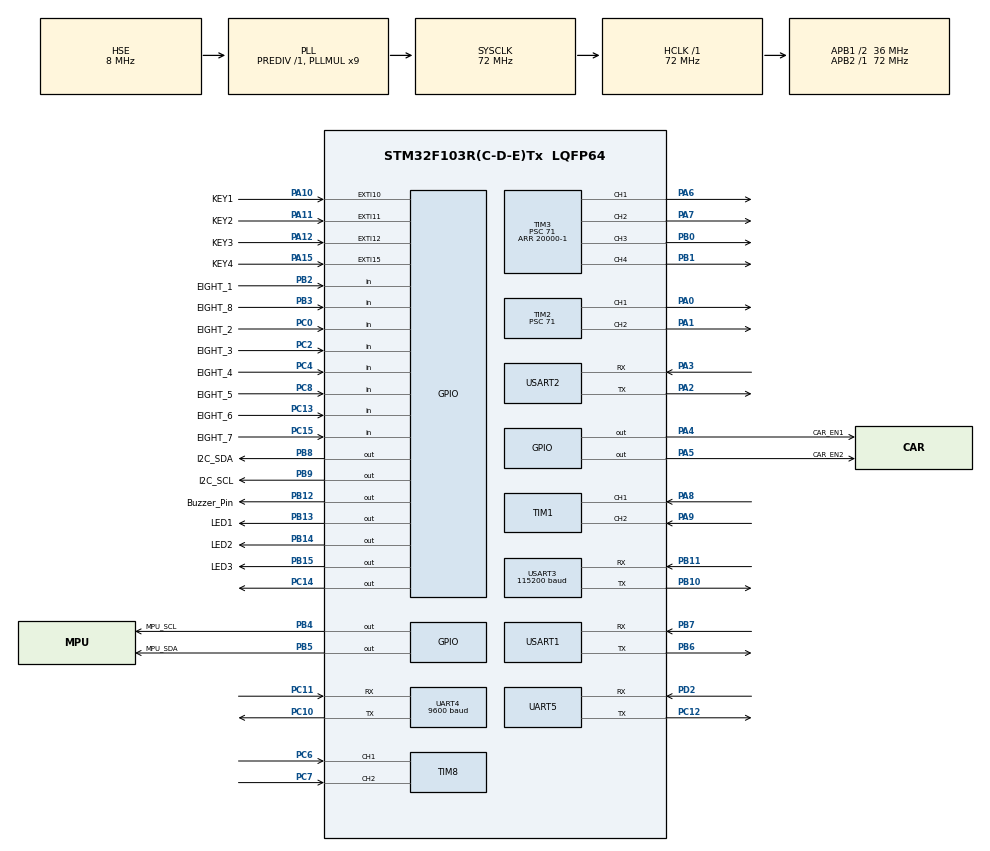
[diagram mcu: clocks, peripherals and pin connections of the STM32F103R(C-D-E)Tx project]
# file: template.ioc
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Dma.Request0=USART3_TX
Dma.Request1=USART3_RX
Dma.Request2=USART2_RX
Dma.Request3=USART2_TX
Dma.Request4=UART4_RX
Dma.Request5=UART4_TX
Dma.UART4_RX.4.Direction=DMA_PERIPH_TO_MEMORY
Dma.UART4_RX.4.Instance=DMA2_Channel3
Dma.UART4_RX.4.MemDataAlignment=DMA_MDATAALIGN_BYTE
Dma.UART4_RX.4.MemInc=DMA_MINC_ENABLE
Dma.UART4_RX.4.Mode=DMA_NORMAL
Dma.UART4_RX.4.PeriphDataAlignment=DMA_PDATAALIGN_BYTE
Dma.UART4_RX.4.PeriphInc=DMA_PINC_DISABLE
Dma.UART4_RX.4.Priority=DMA_PRIORITY_LOW
Dma.UART4_TX.5.Direction=DMA_MEMORY_TO_PERIPH
Dma.UART4_TX.5.Instance=DMA2_Channel5
Dma.UART4_TX.5.MemDataAlignment=DMA_MDATAALIGN_BYTE
Dma.UART4_TX.5.MemInc=DMA_MINC_ENABLE
Dma.UART4_TX.5.Mode=DMA_NORMAL
Dma.UART4_TX.5.PeriphDataAlignment=DMA_PDATAALIGN_BYTE
Dma.UART4_TX.5.PeriphInc=DMA_PINC_DISABLE
Dma.UART4_TX.5.Priority=DMA_PRIORITY_LOW
Dma.USART2_RX.2.Direction=DMA_PERIPH_TO_MEMORY
Dma.USART2_RX.2.Instance=DMA1_Channel6
Dma.USART2_RX.2.MemDataAlignment=DMA_MDATAALIGN_BYTE
Dma.USART2_RX.2.MemInc=DMA_MINC_ENABLE
Dma.USART2_RX.2.Mode=DMA_NORMAL
Dma.USART2_RX.2.PeriphDataAlignment=DMA_PDATAALIGN_BYTE
Dma.USART2_RX.2.PeriphInc=DMA_PINC_DISABLE
Dma.USART2_RX.2.Priority=DMA_PRIORITY_LOW
Dma.USART2_TX.3.Direction=DMA_MEMORY_TO_PERIPH
Dma.USART2_TX.3.Instance=DMA1_Channel7
Dma.USART2_TX.3.MemDataAlignment=DMA_MDATAALIGN_BYTE
Dma.USART2_TX.3.MemInc=DMA_MINC_ENABLE
Dma.USART2_TX.3.Mode=DMA_NORMAL
Dma.USART2_TX.3.PeriphDataAlignment=DMA_PDATAALIGN_BYTE
Dma.USART2_TX.3.PeriphInc=DMA_PINC_DISABLE
Dma.USART2_TX.3.Priority=DMA_PRIORITY_LOW
Dma.USART3_RX.1.Direction=DMA_PERIPH_TO_MEMORY
Dma.USART3_RX.1.Instance=DMA1_Channel3
Dma.USART3_RX.1.MemDataAlignment=DMA_MDATAALIGN_BYTE
Dma.USART3_RX.1.MemInc=DMA_MINC_ENABLE
Dma.USART3_RX.1.Mode=DMA_NORMAL
Dma.USART3_RX.1.PeriphDataAlignment=DMA_PDATAALIGN_BYTE
Dma.USART3_RX.1.PeriphInc=DMA_PINC_DISABLE
Dma.USART3_RX.1.Priority=DMA_PRIORITY_LOW
Dma.USART3_TX.0.Direction=DMA_MEMORY_TO_PERIPH
Dma.USART3_TX.0.Instance=DMA1_Channel2
Dma.USART3_TX.0.MemDataAlignment=DMA_MDATAALIGN_BYTE
Dma.USART3_TX.0.MemInc=DMA_MINC_ENABLE
Dma.USART3_TX.0.Mode=DMA_NORMAL
Dma.USART3_TX.0.PeriphDataAlignment=DMA_PDATAALIGN_BYTE
Dma.USART3_TX.0.PeriphInc=DMA_PINC_DISABLE
Dma.USART3_TX.0.Priority=DMA_PRIORITY_LOW
Mcu.Family=STM32F1
Mcu.Name=STM32F103R(C-D-E)Tx
Mcu.Package=LQFP64
NVIC.DMA1_Channel2_IRQn=true\:0\:0\:false\:false\:true\:false\:true\:true
NVIC.DMA1_Channel3_IRQn=true\:0\:0\:false\:false\:true\:false\:true\:true
NVIC.DMA1_Channel6_IRQn=true\:0\:0\:false\:false\:true\:false\:true\:true
NVIC.DMA1_Channel7_IRQn=true\:0\:0\:false\:false\:true\:false\:true\:true
NVIC.DMA2_Channel3_IRQn=true\:0\:0\:false\:false\:true\:false\:true\:true
NVIC.DMA2_Channel4_5_IRQn=true\:0\:0\:false\:false\:true\:false\:true\:true
NVIC.EXTI15_10_IRQn=true\:1\:0\:true\:false\:true\:true\:true\:true
NVIC.PriorityGroup=NVIC_PRIORITYGROUP_4
NVIC.TIM1_UP_IRQn=true\:0\:0\:false\:false\:true\:true\:true\:true
NVIC.TIM2_IRQn=true\:2\:0\:true\:false\:true\:true\:true\:true
NVIC.TIM8_UP_IRQn=true\:0\:0\:false\:false\:true\:true\:true\:true
NVIC.UART4_IRQn=true\:2\:0\:true\:false\:true\:true\:true\:true
NVIC.USART1_IRQn=true\:2\:0\:true\:false\:true\:true\:true\:true
NVIC.USART2_IRQn=true\:2\:0\:true\:false\:true\:true\:true\:true
NVIC.USART3_IRQn=true\:2\:0\:true\:false\:true\:true\:true\:true
PA0-WKUP.Signal=S_TIM2_CH1_ETR
PA1.Signal=S_TIM2_CH2
PA10.GPIO_Label=KEY1
PA10.GPIO_PuPd=GPIO_PULLDOWN
PA10.Signal=GPXTI10
PA11.GPIO_Label=KEY2
PA11.GPIO_PuPd=GPIO_PULLDOWN
PA11.Signal=GPXTI11
PA12.GPIO_Label=KEY3
PA12.GPIO_PuPd=GPIO_PULLDOWN
PA12.Signal=GPXTI12
PA13.Mode=Serial_Wire
PA13.Signal=SYS_JTMS-SWDIO
PA14.Mode=Serial_Wire
PA14.Signal=SYS_JTCK-SWCLK
PA15.GPIO_Label=KEY4
PA15.GPIO_PuPd=GPIO_PULLDOWN
PA15.Signal=GPXTI15
PA2.Mode=Asynchronous
PA2.Signal=USART2_TX
PA3.Mode=Asynchronous
PA3.Signal=USART2_RX
PA4.GPIO_Label=CAR_EN1
PA4.Signal=GPIO_Output
PA5.GPIO_Label=CAR_EN2
PA5.Signal=GPIO_Output
PA6.Signal=S_TIM3_CH1
PA7.Signal=S_TIM3_CH2
PA8.Signal=S_TIM1_CH1
PA9.Signal=S_TIM1_CH2
PB0.Signal=S_TIM3_CH3
PB1.Signal=S_TIM3_CH4
PB10.Mode=Asynchronous
PB10.Signal=USART3_TX
PB11.Mode=Asynchronous
PB11.Signal=USART3_RX
PB12.GPIO_Label=Buzzer_Pin
PB12.GPIO_PuPd=GPIO_PULLUP
PB12.Signal=GPIO_Output
PB13.GPIO_Label=LED1
PB13.Signal=GPIO_Output
PB14.GPIO_Label=LED2
PB14.PinState=GPIO_PIN_SET
PB14.Signal=GPIO_Output
PB15.GPIO_Label=LED3
PB15.PinState=GPIO_PIN_SET
PB15.Signal=GPIO_Output
PB2.GPIO_Label=EIGHT_1
PB2.Signal=GPIO_Input
PB3.GPIO_Label=EIGHT_8
PB3.GPIO_PuPd=GPIO_PULLUP
PB3.Signal=GPIO_Input
PB4.GPIO_Label=MPU_SCL
PB4.Signal=GPIO_Output
PB5.GPIO_Label=MPU_SDA
PB5.Signal=GPIO_Output
PB6.Mode=Asynchronous
PB6.Signal=USART1_TX
PB7.Mode=Asynchronous
PB7.Signal=USART1_RX
PB8.GPIO_Label=I2C_SDA
PB8.Signal=GPIO_Output
PB9.GPIO_Label=I2C_SCL
PB9.Signal=GPIO_Output
PC0.GPIO_Label=EIGHT_2
PC0.Signal=GPIO_Input
PC10.Mode=Asynchronous
PC10.Signal=UART4_TX
PC11.Mode=Asynchronous
PC11.Signal=UART4_RX
PC12.Mode=Asynchronous
PC12.Signal=UART5_TX
PC13-TAMPER-RTC.GPIO_Label=EIGHT_6
PC13-TAMPER-RTC.Signal=GPIO_Input
PC14-OSC32_IN.Signal=GPIO_Output
PC15-OSC32_OUT.GPIO_Label=EIGHT_7
PC15-OSC32_OUT.Signal=GPIO_Input
PC2.GPIO_Label=EIGHT_3
PC2.Signal=GPIO_Input
PC4.GPIO_Label=EIGHT_4
PC4.Signal=GPIO_Input
PC6.Signal=S_TIM8_CH1
PC7.Signal=S_TIM8_CH2
PC8.GPIO_Label=EIGHT_5
PC8.Signal=GPIO_Input
PD0-OSC_IN.Mode=HSE-External-Oscillator
PD0-OSC_IN.Signal=RCC_OSC_IN
PD1-OSC_OUT.Mode=HSE-External-Oscillator
PD1-OSC_OUT.Signal=RCC_OSC_OUT
PD2.Mode=Asynchronous
PD2.Signal=UART5_RX
ProjectManager.HeapSize=0x200
ProjectManager.StackSize=0x400
ProjectManager.TargetToolchain=MDK-ARM V5.32
RCC.AHBFreq_Value=72000000
RCC.APB1CLKDivider=RCC_HCLK_DIV2
RCC.APB1Freq_Value=36000000
RCC.APB1TimFreq_Value=72000000
RCC.APB2Freq_Value=72000000
RCC.APB2TimFreq_Value=72000000
RCC.HCLKFreq_Value=72000000
RCC.PLLMUL=RCC_PLL_MUL9
RCC.PLLSourceVirtual=RCC_PLLSOURCE_HSE
RCC.SYSCLKFreq_VALUE=72000000
RCC.SYSCLKSource=RCC_SYSCLKSOURCE_PLLCLK
RCC.USBFreq_Value=72000000
SH.S_TIM1_CH1.0=TIM1_CH1,Encoder_Interface
SH.S_TIM1_CH2.0=TIM1_CH2,Encoder_Interface
SH.S_TIM2_CH1_ETR.0=TIM2_CH1,PWM Generation1 CH1
SH.S_TIM2_CH2.0=TIM2_CH2,PWM Generation2 CH2
SH.S_TIM3_CH1.0=TIM3_CH1,PWM Generation1 CH1
SH.S_TIM3_CH2.0=TIM3_CH2,PWM Generation2 CH2
SH.S_TIM3_CH3.0=TIM3_CH3,PWM Generation3 CH3
SH.S_TIM3_CH4.0=TIM3_CH4,PWM Generation4 CH4
SH.S_TIM8_CH1.0=TIM8_CH1,Encoder_Interface
SH.S_TIM8_CH2.0=TIM8_CH2,Encoder_Interface
TIM1.EncoderMode=TIM_ENCODERMODE_TI12
TIM2.AutoReloadPreload=TIM_AUTORELOAD_PRELOAD_ENABLE
TIM2.Channel-PWM\ Generation1\ CH1=TIM_CHANNEL_1
TIM2.Channel-PWM\ Generation2\ CH2=TIM_CHANNEL_2
TIM2.Period=999
TIM2.Prescaler=71
TIM3.Channel-PWM\ Generation1\ CH1=TIM_CHANNEL_1
TIM3.Channel-PWM\ Generation2\ CH2=TIM_CHANNEL_2
TIM3.Channel-PWM\ Generation3\ CH3=TIM_CHANNEL_3
TIM3.Channel-PWM\ Generation4\ CH4=TIM_CHANNEL_4
TIM3.Period=20000-1
TIM3.Prescaler=71
TIM8.EncoderMode=TIM_ENCODERMODE_TI12
UART4.BaudRate=9600
UART4.VirtualMode=Asynchronous
UART5.VirtualMode=Asynchronous
USART1.VirtualMode=VM_ASYNC
USART2.VirtualMode=VM_ASYNC
USART3.BaudRate=115200
USART3.VirtualMode=VM_ASYNC
VP_TIM2_VS_ClockSourceINT.Mode=Internal
board=custom

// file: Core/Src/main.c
/* USER CODE BEGIN Header */
/**
  ******************************************************************************
  * @file           : main.c
  * @brief          : Main program body
  ******************************************************************************
  * @attention
  *
  * Copyright (c) 2024 STMicroelectronics.
  * All rights reserved.
  *
  * This software is licensed under terms that can be found in the LICENSE file
  * in the root directory of this software component.
  * If no LICENSE file comes with this software, it is provided AS-IS.
  *
  ******************************************************************************
  */
/* USER CODE END Header */
#include "main.h"
#include "dma.h"
#include "tim.h"
#include "usart.h"
#include "gpio.h"

/* USER CODE BEGIN Includes */
#include "app.h"
/* USER CODE END Includes */

void SystemClock_Config(void);

int main(void)
{

  /* MCU Configuration--------------------------------------------------------*/

  /* Reset of all peripherals, Initializes the Flash interface and the Systick. */
  HAL_Init();

  /* Configure the system clock */
  SystemClock_Config();

  /* Initialize all configured peripherals */
  MX_GPIO_Init();
  MX_DMA_Init();
  MX_UART4_Init();
  MX_USART1_UART_Init();
  MX_TIM1_Init();
  MX_TIM2_Init();
  MX_TIM3_Init();
  MX_TIM8_Init();
  MX_UART5_Init();
  MX_USART2_UART_Init();
  MX_USART3_UART_Init();
  /* USER CODE BEGIN 2 */
	App_Init();
  /* USER CODE END 2 */

  /* Infinite loop */
  while (1)
  {

    /* USER CODE BEGIN 3 */
		App_Task();
  }
  /* USER CODE END 3 */
}

void SystemClock_Config(void)
{
  RCC_OscInitTypeDef RCC_OscInitStruct = {0};
  RCC_ClkInitTypeDef RCC_ClkInitStruct = {0};

  /** Initializes the RCC Oscillators according to the specified parameters
  * in the RCC_OscInitTypeDef structure.
  */
  RCC_OscInitStruct.OscillatorType = RCC_OSCILLATORTYPE_HSE;
  RCC_OscInitStruct.HSEState = RCC_HSE_ON;
  RCC_OscInitStruct.HSEPredivValue = RCC_HSE_PREDIV_DIV1;
  RCC_OscInitStruct.HSIState = RCC_HSI_ON;
  RCC_OscInitStruct.PLL.PLLState = RCC_PLL_ON;
  RCC_OscInitStruct.PLL.PLLSource = RCC_PLLSOURCE_HSE;
  RCC_OscInitStruct.PLL.PLLMUL = RCC_PLL_MUL9;
  if (HAL_RCC_OscConfig(&RCC_OscInitStruct) != HAL_OK)
  {
    Error_Handler();
  }

  /** Initializes the CPU, AHB and APB buses clocks
  */
  RCC_ClkInitStruct.ClockType = RCC_CLOCKTYPE_HCLK|RCC_CLOCKTYPE_SYSCLK
                              |RCC_CLOCKTYPE_PCLK1|RCC_CLOCKTYPE_PCLK2;
  RCC_ClkInitStruct.SYSCLKSource = RCC_SYSCLKSOURCE_PLLCLK;
  RCC_ClkInitStruct.AHBCLKDivider = RCC_SYSCLK_DIV1;
  RCC_ClkInitStruct.APB1CLKDivider = RCC_HCLK_DIV2;
  RCC_ClkInitStruct.APB2CLKDivider = RCC_HCLK_DIV1;

  if (HAL_RCC_ClockConfig(&RCC_ClkInitStruct, FLASH_LATENCY_2) != HAL_OK)
  {
    Error_Handler();
  }
}

void Error_Handler(void)
{
  __disable_irq();
  while (1)
  {
  }
}
